# FM33A0XXER register map
File version: 1.0
CPU: SC000, little endian, no MPU, no FPU, 3 interrupt priority bits
Registers are 32-bit, read-write, reset 0x0 unless marked. A register's access mark holds for its fields unless they carry their own. Offsets are from the block's base; [hi:lo] are bit positions; {n}, {i} and the like mark numbered series.

## CMU — CMU module information
Base 0x40002400
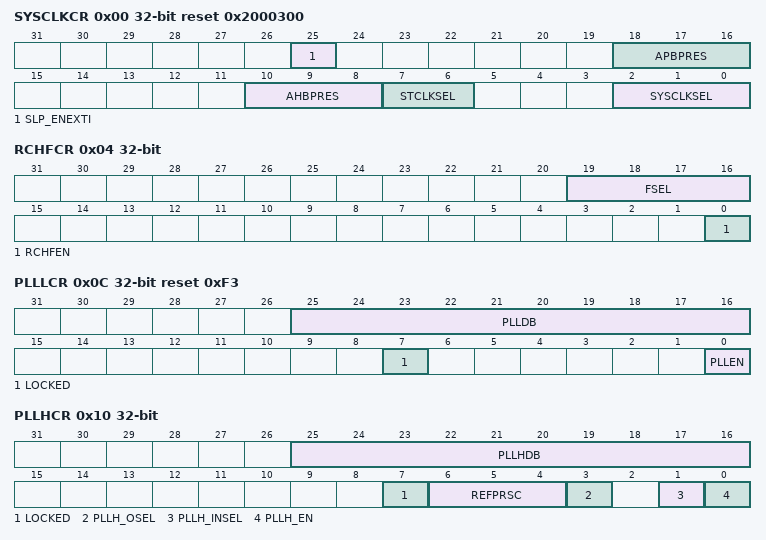
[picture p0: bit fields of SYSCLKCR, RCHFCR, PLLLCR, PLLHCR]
0x00 SYSCLKCR reset 0x2000300 — System Clock Control Register
  [25] SLP_ENEXTI — SLP_ENEXTI field description
  [18:16] APBPRES — APBPRES field description
  [10:8] AHBPRES — AHBPRES field description
  [7:6] STCLKSEL — STCLKSEL field description
  [2:0] SYSCLKSEL — SYSCLKSEL field description
0x04 RCHFCR — RCHF Control Register
  [19:16] FSEL — FSEL field description
  [0] RCHFEN — RCHFEN field description
0x08 RCHFTR — RCHF Trim Register
  [7:0] RCHFTRIM — RCHFTRIM field description
0x0C PLLLCR reset 0xF3 — PLL_L Control Register
  [25:16] PLLDB — PLLDB field description
  [7] LOCKED ro — LOCKED field description
  [0] PLLEN — PLLEN field description
0x10 PLLHCR — PLL_H Control Register
  [25:16] PLLHDB — PLLHDB field description
  [7] LOCKED ro — LOCKED field description
  [6:4] REFPRSC — REFPRSC field description
  [3] PLLH_OSEL — PLLH_OSEL field description
  [1] PLLH_INSEL — PLLH_INSEL field description
  [0] PLLH_EN — PLLH_EN field description
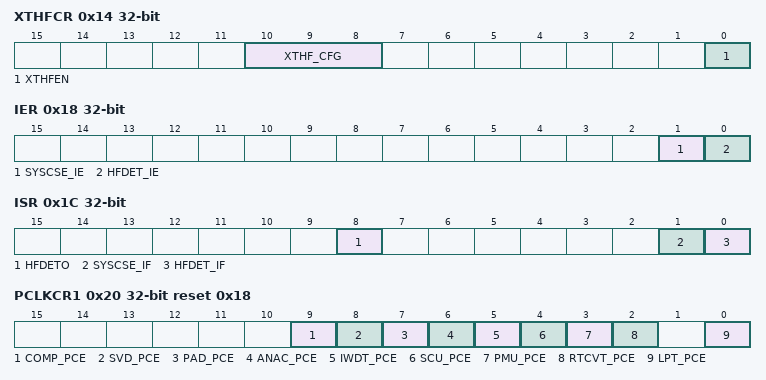
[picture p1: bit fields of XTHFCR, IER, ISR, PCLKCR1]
0x14 XTHFCR — XTHF Control Register
  [10:8] XTHF_CFG — XTHF_CFG field description
  [0] XTHFEN — XTHFEN field description
0x18 IER — CMU Interrupt Enable Register
  [1] SYSCSE_IE — SYSCSE_IE field description
  [0] HFDET_IE — HFDET_IE field description
0x1C ISR — CMU Interrupt Status Register
  [8] HFDETO ro — HFDETO field description
  [1] SYSCSE_IF — SYSCSE_IF field description
  [0] HFDET_IF — HFDET_IF field description
0x20 PCLKCR1 reset 0x18 — Peripheral bus Clock Control Register1
  [9] COMP_PCE — COMP_PCE field description
  [8] SVD_PCE — SVD_PCE field description
  [7] PAD_PCE — PAD_PCE field description
  [6] ANAC_PCE — ANAC_PCE field description
  [5] IWDT_PCE — IWDT_PCE field description
  [4] SCU_PCE — SCU_PCE field description
  [3] PMU_PCE — PMU_PCE field description
  [2] RTCVT_PCE — RTCVT_PCE field description
  [0] LPT_PCE — LPT_PCE field description
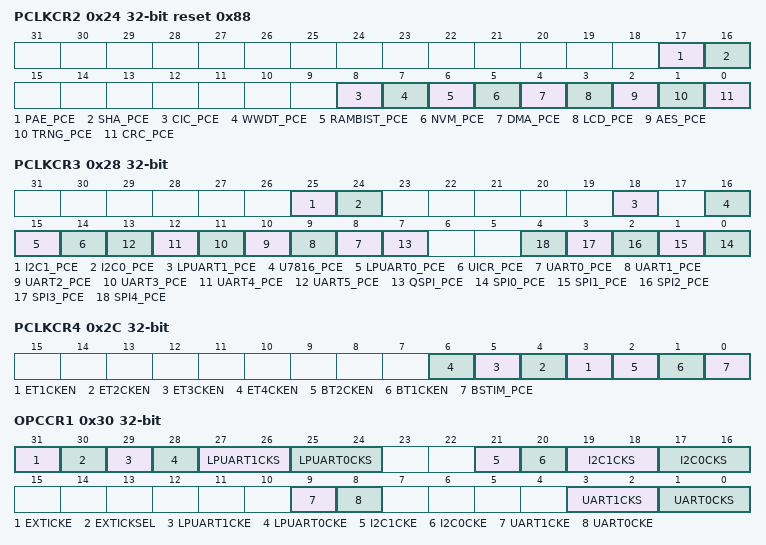
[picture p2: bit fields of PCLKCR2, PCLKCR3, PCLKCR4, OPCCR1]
0x24 PCLKCR2 reset 0x88 — Peripheral bus Clock Control Register2
  [17] PAE_PCE — PAE_PCE field description
  [16] SHA_PCE — SHA_PCE field description
  [8] CIC_PCE — CIC_PCE field description
  [7] WWDT_PCE — WWDT_PCE field description
  [6] RAMBIST_PCE — RAMBIST_PCE field description
  [5] NVM_PCE — NVM_PCE field description
  [4] DMA_PCE — DMA_PCE field description
  [3] LCD_PCE — LCD_PCE field description
  [2] AES_PCE — AES_PCE field description
  [1] TRNG_PCE — TRNG_PCE field description
  [0] CRC_PCE — CRC_PCE field description
0x28 PCLKCR3 — Peripheral bus Clock Control Register3
  [25] I2C1_PCE — I2C1_PCE field description
  [24] I2C0_PCE — I2C0_PCE field description
  [18] LPUART1_PCE — LPUART1_PCE field description
  [16] U7816_PCE — U7816_PCE field description
  [15] LPUART0_PCE — LPUART0_PCE field description
  [14] UICR_PCE — UICR_PCE field description
  [n+8] UART{n}_PCE (n=0..5) — UART{n}_PCE field description
  [7] QSPI_PCE — QSPI_PCE field description
  [n] SPI{n}_PCE (n=0..4) — SPI{n}_PCE field description
0x2C PCLKCR4 — Peripheral bus Clock Control Register4
  [n+2] ET{n}CKEN (n=1..4) — ET{n}CKEN field description
  [2] BT2CKEN — BT2CKEN field description
  [1] BT1CKEN — BT1CKEN field description
  [0] BSTIM_PCE — BSTIM_PCE field description
0x30 OPCCR1 — Peripheral Operation Clock Control Register1
  [31] EXTICKE — EXTICKE field description
  [30] EXTICKSEL — EXTICKSEL field description
  [29] LPUART1CKE — LPUART1CKE field description
  [28] LPUART0CKE — LPUART0CKE field description
  [27:26] LPUART1CKS — LPUART1CKS field description
  [25:24] LPUART0CKS — LPUART0CKS field description
  [21] I2C1CKE — I2C1CKE field description
  [20] I2C0CKE — I2C0CKE field description
  [19:18] I2C1CKS — I2C1CKS field description
  [17:16] I2C0CKS — I2C0CKS field description
  [9] UART1CKE — UART1CKE field description
  [8] UART0CKE — UART0CKE field description
  [3:2] UART1CKS — UART1CKS field description
  [1:0] UART0CKS — UART0CKS field description
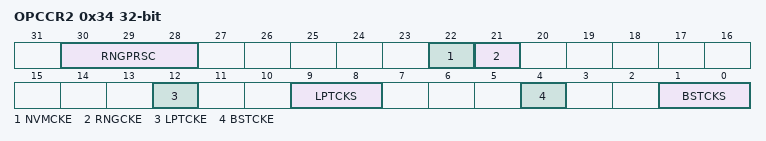
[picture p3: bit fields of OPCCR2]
0x34 OPCCR2 — Peripheral Operation Clock Control Register2
  [30:28] RNGPRSC — RNGPRSC field description
  [22] NVMCKE — NVMCKE field description
  [21] RNGCKE — RNGCKE field description
  [12] LPTCKE — LPTCKE field description
  [9:8] LPTCKS — LPTCKS field description
  [4] BSTCKE — BSTCKE field description
  [1:0] BSTCKS — BSTCKS field description
